# PY32F303 register map
Vendor: PUYA Co.Ltd; Series: ARMCM4; File version: 1.2
CPU: CM4 r0p1, little endian, MPU, FPU, 4 interrupt priority bits
Registers are 32-bit, read-write, reset 0x0 unless marked. A register's access mark holds for its fields unless they carry their own. Offsets are from the block's base; [hi:lo] are bit positions; {n}, {i} and the like mark numbered series.

## ADC1 — desc ADC
Base 0x40012400
Same registers: ADC2 0x40012800, ADC3 0x40013C00
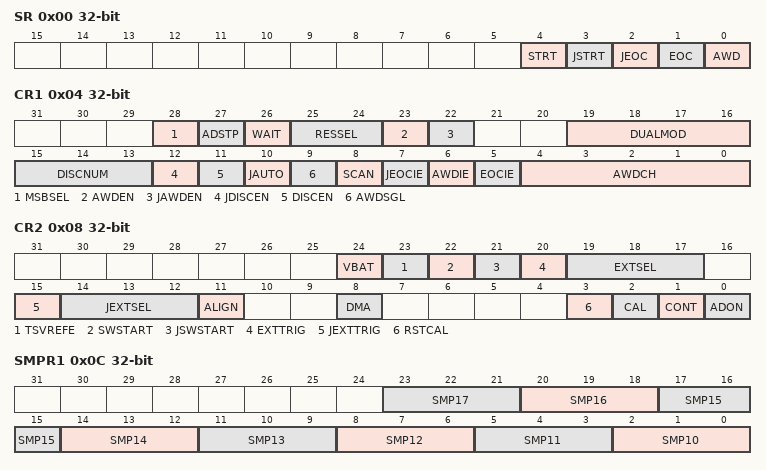
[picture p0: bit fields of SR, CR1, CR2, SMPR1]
0x00 SR
  [4] STRT, [3] JSTRT, [2] JEOC, [1] EOC, [0] AWD
0x04 CR1
  [28] MSBSEL, [27] ADSTP, [26] WAIT, [25:24] RESSEL, [23] AWDEN, [22] JAWDEN, [19:16] DUALMOD, [15:13] DISCNUM, [12] JDISCEN, [11] DISCEN, [10] JAUTO, [9] AWDSGL, [8] SCAN, [7] JEOCIE, [6] AWDIE, [5] EOCIE, [4:0] AWDCH
0x08 CR2
  [24] VBAT, [23] TSVREFE, [22] SWSTART, [21] JSWSTART, [20] EXTTRIG, [19:17] EXTSEL, [15] JEXTTRIG, [14:12] JEXTSEL, [11] ALIGN, [8] DMA, [3] RSTCAL, [2] CAL, [1] CONT, [0] ADON
0x0C SMPR1
  [3n-28:3n-30] SMP{n} (n=10..17)
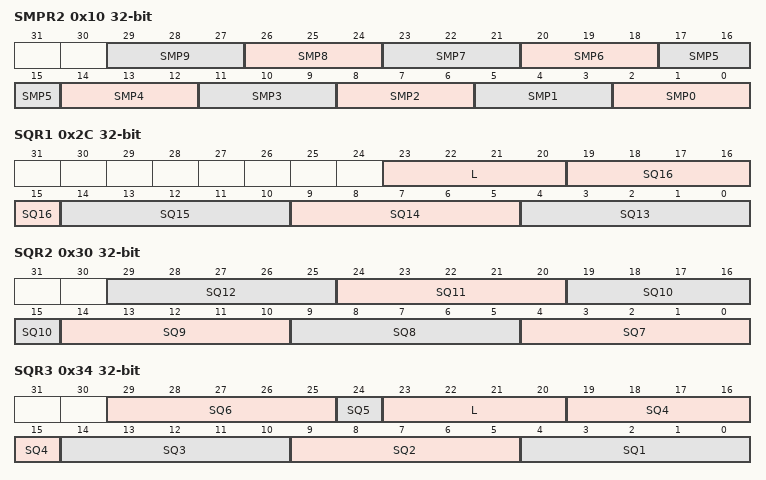
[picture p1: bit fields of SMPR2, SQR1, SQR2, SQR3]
0x10 SMPR2
  [3n+2:3n] SMP{n} (n=0..9)
{0x10+4i} JOFR{i} (i=1..4)
  [11:0] JOFFSET{i}
0x24 HTR
  [11:0] HT
0x28 LTR
  [11:0] LT
0x2C SQR1
  [23:20] L, [5n-61:5n-65] SQ{n} (n=13..16)
0x30 SQR2
  [5n-31:5n-35] SQ{n} (n=7..12)
0x34 SQR3
  [29:25] SQ6, [24] SQ5, [23:20] L wo, [5n-1:5n-5] SQ{n} (n=1..4)
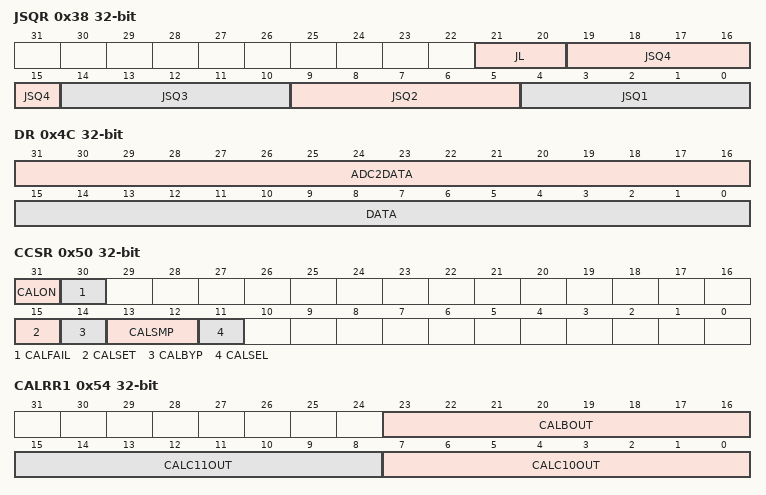
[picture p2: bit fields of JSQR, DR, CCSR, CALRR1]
0x38 JSQR
  [21:20] JL, [5n-1:5n-5] JSQ{n} (n=1..4)
{0x38+4i} JDR{i} ro (i=1..4)
  [15:0] JDR{i}
0x4C DR ro
  [31:16] ADC2DATA, [15:0] DATA
0x50 CCSR
  [31] CALON ro, [30] CALFAIL, [15] CALSET, [14] CALBYP, [13:12] CALSMP, [11] CALSEL
0x54 CALRR1 ro
  [23:16] CALBOUT, [15:8] CALC11OUT, [7:0] CALC10OUT
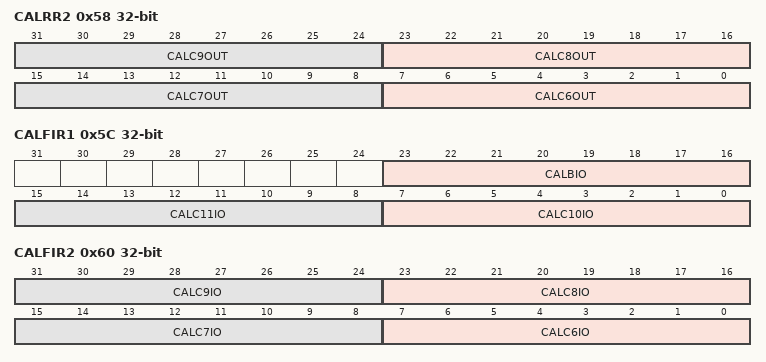
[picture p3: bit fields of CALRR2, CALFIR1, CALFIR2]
0x58 CALRR2 ro
  [8n-41:8n-48] CALC{n}OUT (n=6..9)
0x5C CALFIR1
  [23:16] CALBIO, [15:8] CALC11IO, [7:0] CALC10IO
0x60 CALFIR2
  [8n-41:8n-48] CALC{n}IO (n=6..9)

## BKP
Base 0x40006C00
{0x0+4i} DR{i} (i=1..10)
  [15:0] D
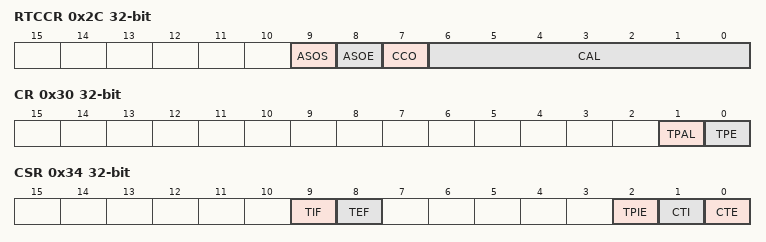
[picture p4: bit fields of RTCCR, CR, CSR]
0x2C RTCCR
  [9] ASOS, [8] ASOE, [7] CCO, [6:0] CAL
0x30 CR
  [1] TPAL, [0] TPE
0x34 CSR
  [9] TIF ro, [8] TEF ro, [2] TPIE, [1] CTI wo, [0] CTE wo
{0x14+4i} DR{i} (i=11..42)
  [15:0] D

## CANFD
Base 0x40008000
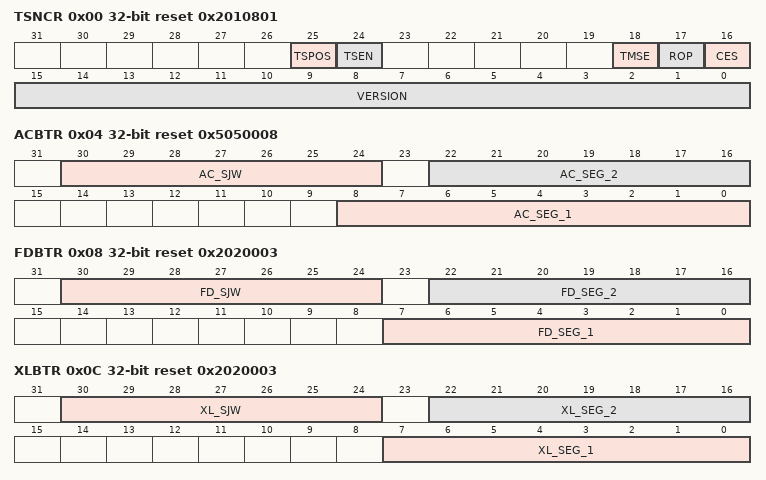
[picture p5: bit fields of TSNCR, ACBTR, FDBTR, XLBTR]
0x00 TSNCR reset 0x2010801
  [25] TSPOS, [24] TSEN, [18] TMSE, [17] ROP, [16] CES, [15:0] VERSION ro
0x04 ACBTR reset 0x5050008
  [30:24] AC_SJW, [22:16] AC_SEG_2, [8:0] AC_SEG_1
0x08 FDBTR reset 0x2020003
  [30:24] FD_SJW, [22:16] FD_SEG_2, [7:0] FD_SEG_1
0x0C XLBTR reset 0x2020003
  [30:24] XL_SJW, [22:16] XL_SEG_2, [7:0] XL_SEG_1
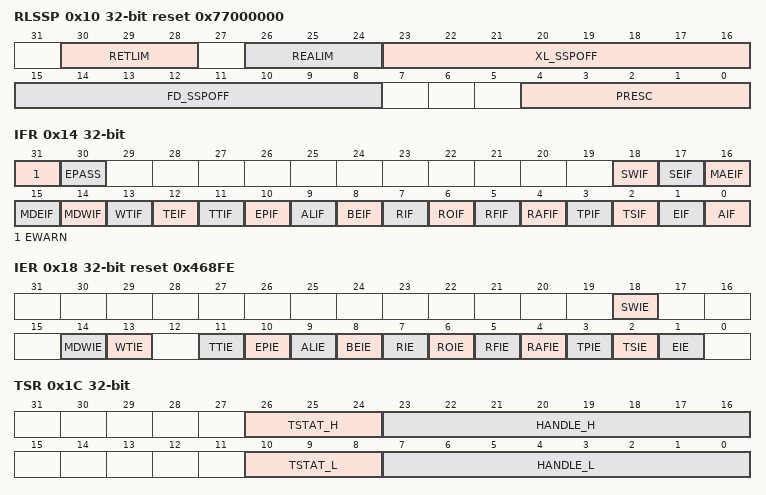
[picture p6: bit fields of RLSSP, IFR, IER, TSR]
0x10 RLSSP reset 0x77000000
  [30:28] RETLIM, [26:24] REALIM, [23:16] XL_SSPOFF, [15:8] FD_SSPOFF, [4:0] PRESC
0x14 IFR
  [31] EWARN ro, [30] EPASS ro, [18] SWIF, [17] SEIF, [16] MAEIF, [15] MDEIF, [14] MDWIF, [13] WTIF, [12] TEIF, [11] TTIF, [10] EPIF, [9] ALIF, [8] BEIF, [7] RIF, [6] ROIF, [5] RFIF, [4] RAFIF, [3] TPIF, [2] TSIF, [1] EIF, [0] AIF
0x18 IER reset 0x468FE
  [18] SWIE, [14] MDWIE, [13] WTIE, [11] TTIE, [10] EPIE, [9] ALIE, [8] BEIE, [7] RIE, [6] ROIE, [5] RFIE, [4] RAFIE, [3] TPIE, [2] TSIE, [1] EIE
0x1C TSR ro
  [26:24] TSTAT_H, [23:16] HANDLE_H, [10:8] TSTAT_L, [7:0] HANDLE_L
0x20 TTSL ro reset 0x2000000
  [31:0] TTS
0x24 TTSH ro reset 0x2000000
  [31:0] TTS
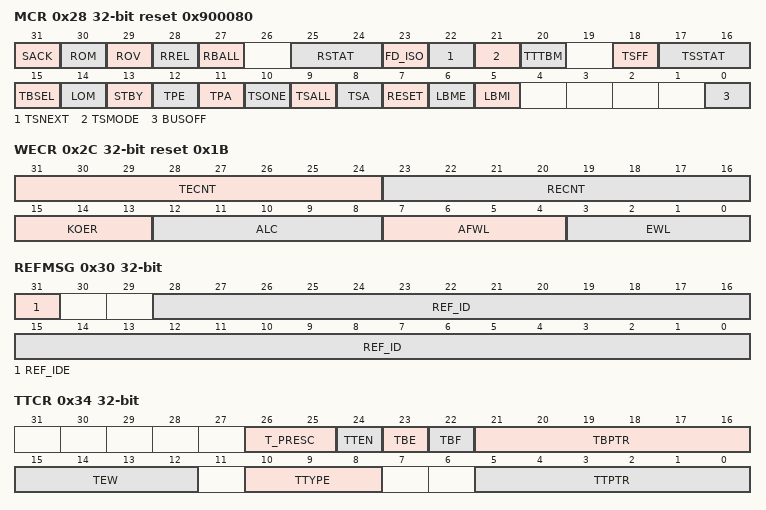
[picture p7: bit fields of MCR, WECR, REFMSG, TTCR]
0x28 MCR reset 0x900080
  [31] SACK, [30] ROM, [29] ROV ro, [28] RREL, [27] RBALL, [25:24] RSTAT ro, [23] FD_ISO, [22] TSNEXT, [21] TSMODE, [20] TTTBM, [18] TSFF ro, [17:16] TSSTAT ro, [15] TBSEL, [14] LOM, [13] STBY, [12] TPE, [11] TPA, [10] TSONE, [9] TSALL, [8] TSA, [7] RESET, [6] LBME, [5] LBMI, [0] BUSOFF
0x2C WECR reset 0x1B
  [31:24] TECNT ro, [23:16] RECNT ro, [15:13] KOER ro, [12:8] ALC ro, [7:4] AFWL, [3:0] EWL
0x30 REFMSG
  [31] REF_IDE, [28:0] REF_ID
0x34 TTCR
  [26:25] T_PRESC, [24] TTEN, [23] TBE, [22] TBF, [21:16] TBPTR, [15:12] TEW, [10:8] TTYPE, [5:0] TTPTR
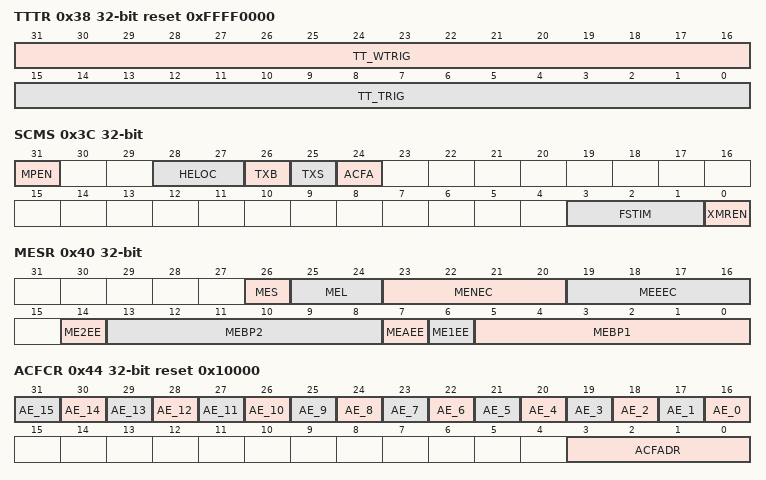
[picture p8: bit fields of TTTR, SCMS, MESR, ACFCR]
0x38 TTTR reset 0xFFFF0000
  [31:16] TT_WTRIG, [15:0] TT_TRIG
0x3C SCMS
  [31] MPEN, [28:27] HELOC ro, [26] TXB ro, [25] TXS ro, [24] ACFA, [3:1] FSTIM, [0] XMREN
0x40 MESR
  [26] MES, [25:24] MEL, [23:20] MENEC, [19:16] MEEEC, [14] ME2EE, [13:8] MEBP2, [7] MEAEE, [6] ME1EE, [5:0] MEBP1
0x44 ACFCR reset 0x10000
  [n+16] AE_{n} (n=0..15), [3:0] ACFADR
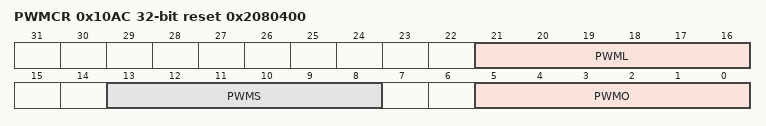
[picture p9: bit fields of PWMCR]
0x10AC PWMCR reset 0x2080400
  [21:16] PWML, [13:8] PWMS, [5:0] PWMO
